# CH564 register map
Vendor: WCH Ltd.; File version: 1.0
Registers are 8-bit, read-write, reset 0x0 unless marked. A register's access mark holds for its fields unless they carry their own. Offsets are from the block's base; [hi:lo] are bit positions; {n}, {i} and the like mark numbered series.

## PFIC — Programmable Fast Interrupt Controller
Base 0xE000E000
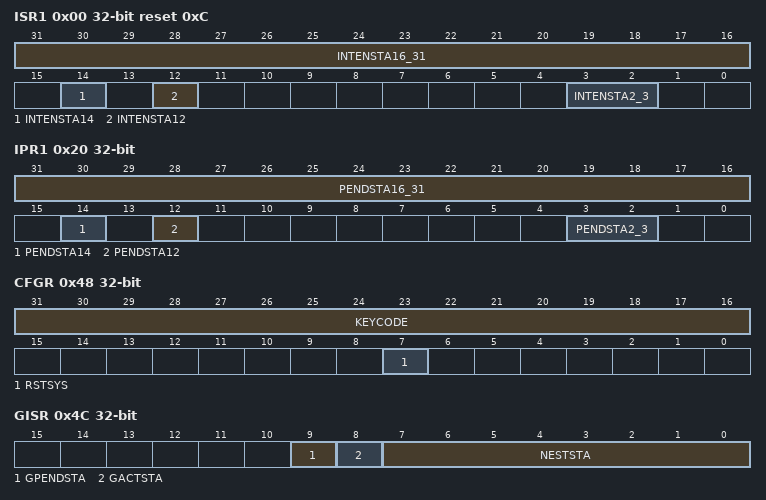
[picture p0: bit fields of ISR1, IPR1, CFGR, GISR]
0x00 ISR1 32-bit ro reset 0xC — Interrupt Status Register
  [31:16] INTENSTA16_31 — Interrupt ID Status
  [14] INTENSTA14 — Interrupt ID Status
  [12] INTENSTA12 — Interrupt ID Status
  [3:2] INTENSTA2_3 — Interrupt ID Status
0x04 ISR2 32-bit ro — Interrupt Status Register
  [7:0] INTENSTA — Interrupt ID Status
0x20 IPR1 32-bit ro — Interrupt Pending Register
  [31:16] PENDSTA16_31 — PENDSTA
  [14] PENDSTA14 — PENDSTA
  [12] PENDSTA12 — PENDSTA
  [3:2] PENDSTA2_3 — PENDSTA
0x24 IPR2 32-bit ro — Interrupt Pending Register
  [7:0] PENDSTA
0x40 ITHRESDR 32-bit — Interrupt Priority Register
  [7:0] THRESHOLD
0x48 CFGR 32-bit wo — Interrupt Config Register
  [31:16] KEYCODE
  [7] RSTSYS — RESETSYS
0x4C GISR 32-bit ro — Interrupt Global Register
  [9] GPENDSTA, [8] GACTSTA, [7:0] NESTSTA
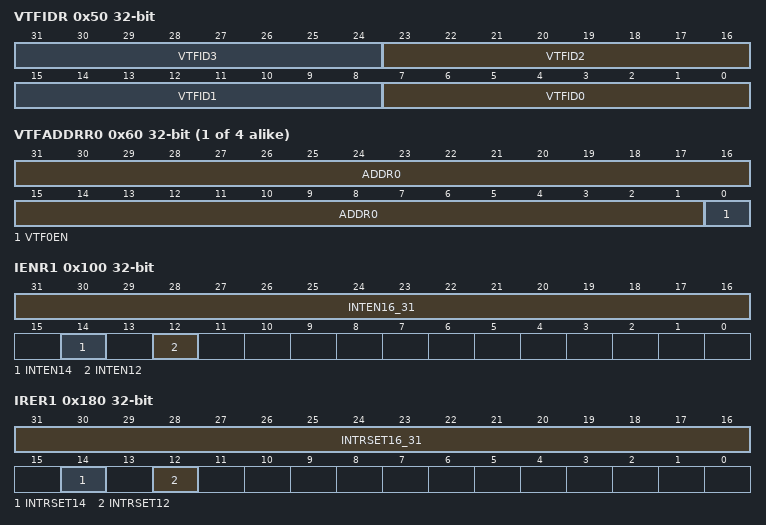
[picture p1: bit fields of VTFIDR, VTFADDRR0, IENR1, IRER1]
0x50 VTFIDR 32-bit — ID Config Register
  [8n+7:8n] VTFID{n} (n=0..3)
{0x60+4i} VTFADDRR{i} 32-bit (i=0..3) — Interrupt {i} address Register
  [31:1] ADDR{i}, [0] VTF{i}EN
0x100 IENR1 32-bit wo — Interrupt Setting Register
  [31:16] INTEN16_31, [14] INTEN14, [12] INTEN12
0x104 IENR2 32-bit wo — Interrupt Setting Register
  [7:0] INTEN
0x180 IRER1 32-bit wo — Interrupt Clear Register
  [31:16] INTRSET16_31 — INTRSET
  [14] INTRSET14 — INTRSET
  [12] INTRSET12 — INTRSET
0x184 IRER2 32-bit wo — Interrupt Clear Register
  [7:0] INTRSET
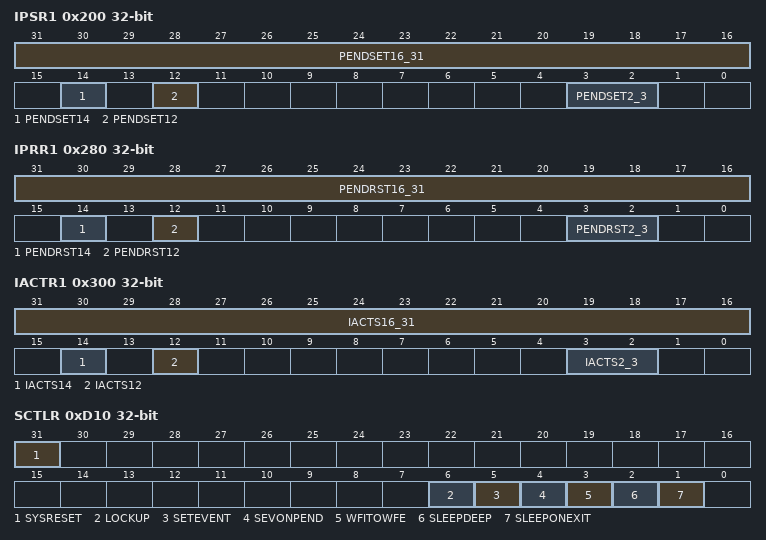
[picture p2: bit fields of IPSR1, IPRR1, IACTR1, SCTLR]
0x200 IPSR1 32-bit wo — Interrupt Pending Register
  [31:16] PENDSET16_31 — PENDSET
  [14] PENDSET14 — PENDSET
  [12] PENDSET12 — PENDSET
  [3:2] PENDSET2_3 — PENDSET
0x204 IPSR2 32-bit wo — Interrupt Pending Register
  [7:0] PENDSET
0x280 IPRR1 32-bit wo — Interrupt Pending Clear Register
  [31:16] PENDRST16_31 — PENDRESET
  [14] PENDRST14 — PENDRESET
  [12] PENDRST12 — PENDRESET
  [3:2] PENDRST2_3 — PENDRESET
0x284 IPRR2 32-bit wo — Interrupt Pending Clear Register
  [7:0] PENDRST — PENDRESET
0x300 IACTR1 32-bit ro — Interrupt ACTIVE Register
  [31:16] IACTS16_31 — IACTS
  [14] IACTS14 — IACTS
  [12] IACTS12 — IACTS
  [3:2] IACTS2_3 — IACTS
0x304 IACTR2 32-bit ro — Interrupt ACTIVE Register
  [7:0] IACTS
{0x400+i} IPRIOR{i} (i=0..68) — Interrupt Priority Register
0xD10 SCTLR 32-bit access per field — System Control Register
  [31] SYSRESET wo, [6] LOCKUP write-write, [5] SETEVENT wo, [4] SEVONPEND write-write, [3] WFITOWFE write-write, [2] SLEEPDEEP rw, [1] SLEEPONEXIT write-write
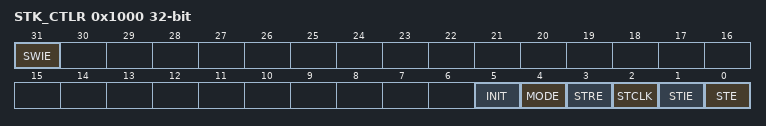
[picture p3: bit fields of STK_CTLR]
0x1000 STK_CTLR 32-bit — System counter control register
  [31] SWIE — System software triggered interrupts enable
  [5] INIT — System Initialization update
  [4] MODE — System Mode
  [3] STRE — System reload register
  [2] STCLK — System selects the clock source
  [1] STIE — System counter interrupt enable
  [0] STE — System counter enable
0x1004 STK_SR 32-bit — System START
  [0] CNTIF
0x1008 STK_CNTL 32-bit — System counter low register
0x100C STK_CNTH 32-bit — System counter high register
0x1010 STK_CMPLR 32-bit — System compare low register
  [31:0] CMPL
0x1014 STK_CMPHR 32-bit — System compare high register
  [31:0] CMPH

## ETHERNET_MMC — Ethernet: MAC management counters
Base 0x40028100
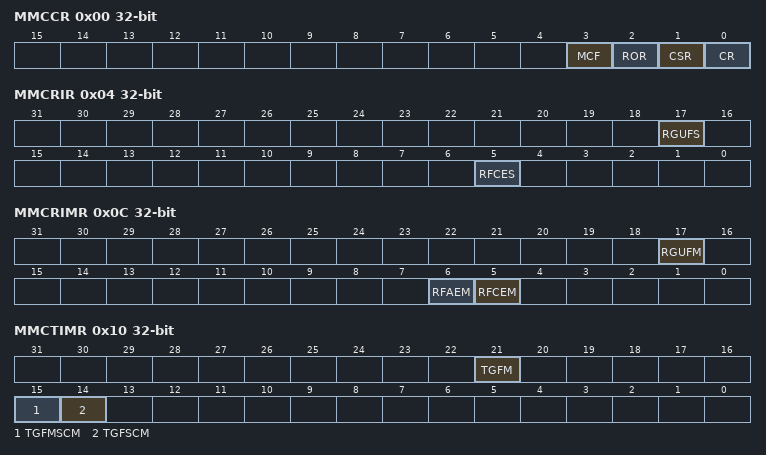
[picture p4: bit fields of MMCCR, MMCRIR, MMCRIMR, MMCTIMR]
0x00 MMCCR 32-bit — Ethernet MMC control register (ETH_MMCCR)
  [3] MCF — MMC counter freeze
  [2] ROR — Reset on read
  [1] CSR — Counter stop rollover
  [0] CR — Counter reset
0x04 MMCRIR 32-bit — Ethernet MMC receive interrupt register (ETH_MMCRIR)
  [17] RGUFS — Received Good Unicast Frames Status
  [5] RFCES — Received frames CRC error status
0x08 MMCTIR 32-bit — Ethernet MMC transmit interrupt register (ETH_MMCTIR)
  [21] TGFS — Transmitted good frames status
0x0C MMCRIMR 32-bit — Ethernet MMC receive interrupt mask register (ETH_MMCRIMR)
  [17] RGUFM — Received good unicast frames mask
  [6] RFAEM — Received frames alignment error mask
  [5] RFCEM — Received frame CRC error mask
0x10 MMCTIMR 32-bit — Ethernet MMC transmit interrupt mask register (ETH_MMCTIMR)
  [21] TGFM — Transmitted good frames mask
  [15] TGFMSCM — Transmitted good frames more single collision mask
  [14] TGFSCM — Transmitted good frames single collision mask
0x4C MMCTGFSCCR 32-bit ro — Ethernet MMC transmitted good frames after a single collision counter
  [31:0] TGFSCC — Transmitted good frames after a single collision counter
0x50 MMCTGFMSCCR 32-bit ro — Ethernet MMC transmitted good frames after more than a single collision
  [31:0] TGFMSCC — Transmitted good frames after more than a single collision counter
0x68 MMCTGFCR 32-bit ro — Ethernet MMC transmitted good frames counter register
  [31:0] TGFC — Transmitted good frames counter
0x94 MMCRFCECR 32-bit ro — Ethernet MMC received frames with CRC error counter register
  [31:0] RFCFC — Received frames with CRC error counter
0x98 MMCRFAECR 32-bit ro — Ethernet MMC received frames with alignment error counter register
  [31:0] RFAEC — Received frames with alignment error counter
0x9C MMCRAFCR 32-bit ro — MMC receive the frame count register
  [31:0] RAFCR — The number of all Ethernet MMC frame received
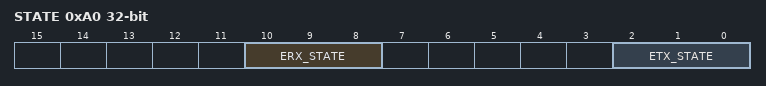
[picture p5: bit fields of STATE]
0xA0 STATE 32-bit ro — Ethernet state machine register
  [10:8] ERX_STATE — Ethernet sending state machine
  [2:0] ETX_STATE — Ethernet receiving state machine
0xC4 MMCRGUFCR 32-bit ro — MMC received good unicast frames counter register
  [31:0] RGUFC — Received good unicast frames counter
